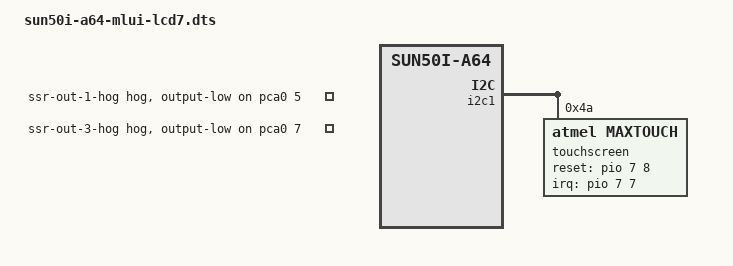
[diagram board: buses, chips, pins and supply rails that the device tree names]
// SPDX-License-Identifier: (GPL-2.0+ OR MIT)
// Copyright (C) 2021 Rudolf J Streif <rudolf.streif@ibeeto.com>
// Based on work of Jagan Teki <jteki@openedev.com>

/dts-v1/;

#include "sun50i-a64.dtsi"
#include "sun50i-a64-cpu-opp.dtsi"
#include "sun50i-a64-mlui.dtsi"

#include <dt-bindings/gpio/gpio.h>
#include <dt-bindings/input/input.h>
#include <dt-bindings/pwm/pwm.h>

/ {
	compatible = "middleby,mlui-lcd7", "middleby,mlui", "allwinner,sun50i-a64";
};


&panel_rgb {
    width-mm = <154>;
    height-mm = <85>;

    panel-timing {
        /* 1024x600 @ 60Hz */
        clock-frequency = <51200000>;
        hactive = <1024>;
        hback-porch = <160>;
        hfront-porch = <160>;
        hsync-len = <100>;
        vactive = <600>;
        vback-porch = <23>;
        vfront-porch = <12>;
        vsync-len = <10>;
    };
};

&backlight {
    brightness-levels = <0 20 30 40 50 60 70 80 90 100>;
    default-brightness-level = <5>;
};

&i2c1 {
    touchscreen@4a {
        compatible = "atmel,maxtouch";
        reg = <0x4a>;
        pinctrl-names = "default";
        pinctrl-0 = <&ctp_pins>;
        interrupt-parent = <&pio>;
        interrupts = <7 7 IRQ_TYPE_EDGE_FALLING>; /* PH7 */
        reset-gpios = <&pio 7 8 GPIO_ACTIVE_HIGH>; /* PH8 */
    };
};

&pca0 {
    ssr-out-1-hog {
        gpio-hog;
        gpios = <5 GPIO_ACTIVE_HIGH>;
        output-low;
    };

    ssr-out-3-hog {
        gpio-hog;
        gpios = <7 GPIO_ACTIVE_HIGH>;
        output-low;
    };
};
